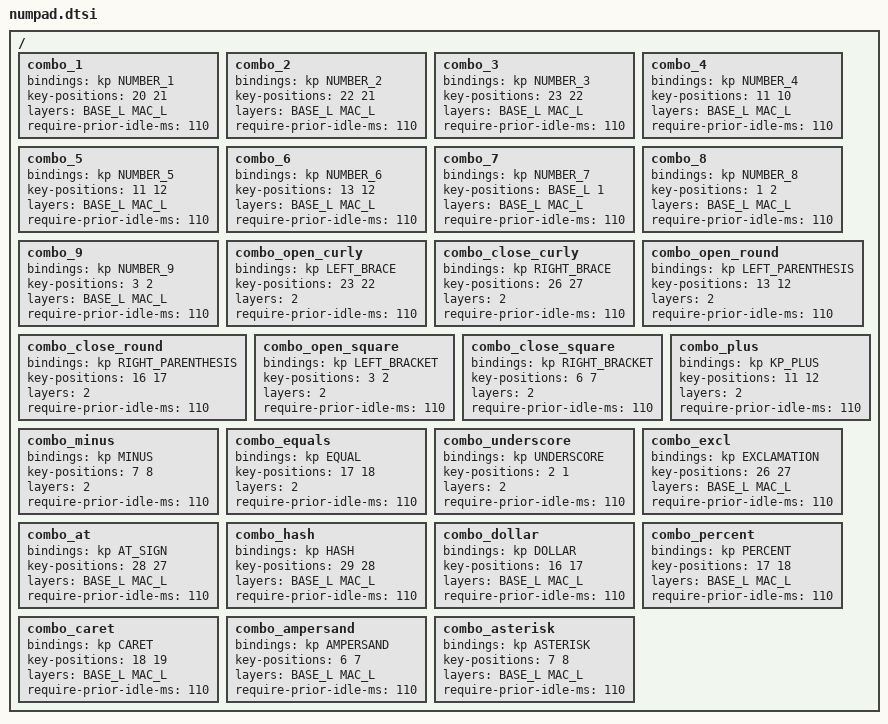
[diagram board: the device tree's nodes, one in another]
/ {
        combo_1 {
            bindings = <&kp NUMBER_1>;
            key-positions = <20 21>;
            layers = <BASE_L MAC_L>;
            require-prior-idle-ms = <110>;
        };
        combo_2 {
            bindings = <&kp NUMBER_2>;
            key-positions = <22 21>;
            layers = <BASE_L MAC_L>;
            require-prior-idle-ms = <110>;
        };
        combo_3 {
            bindings = <&kp NUMBER_3>;
            key-positions = <23 22>;
            layers = <BASE_L MAC_L>;
            require-prior-idle-ms = <110>;
        };
        combo_4 {
            bindings = <&kp NUMBER_4>;
            key-positions = <11 10>;
            layers = <BASE_L MAC_L>;
            require-prior-idle-ms = <110>;
        };
        combo_5 {
            bindings = <&kp NUMBER_5>;
            key-positions = <11 12>;
            layers = <BASE_L MAC_L>;
            require-prior-idle-ms = <110>;
        };
        combo_6 {
            bindings = <&kp NUMBER_6>;
            key-positions = <13 12>;
            layers = <BASE_L MAC_L>;
            require-prior-idle-ms = <110>;
        };
        combo_7 {
            bindings = <&kp NUMBER_7>;
            key-positions = <BASE_L 1>;
            layers = <BASE_L MAC_L>;
            require-prior-idle-ms = <110>;
        };
        combo_8 {
            bindings = <&kp NUMBER_8>;
            key-positions = <1 2>;
            layers = <BASE_L MAC_L>;
            require-prior-idle-ms = <110>;
        };
        combo_9 {
            bindings = <&kp NUMBER_9>;
            key-positions = <3 2>;
            layers = <BASE_L MAC_L>;
            require-prior-idle-ms = <110>;
        };
        // prpgramming combos
        combo_open_curly {
            bindings = <&kp LEFT_BRACE>;
            key-positions = <23 22>;
            layers = <2>;
            require-prior-idle-ms = <110>;
        };
        combo_close_curly {
            bindings = <&kp RIGHT_BRACE>;
            key-positions = <26 27>;
            layers = <2>;
            require-prior-idle-ms = <110>;
        };
        combo_open_round {
            bindings = <&kp LEFT_PARENTHESIS>;
            key-positions = <13 12>;
            layers = <2>;
            require-prior-idle-ms = <110>;
        };
        combo_close_round {
            bindings = <&kp RIGHT_PARENTHESIS>;
            key-positions = <16 17>;
            layers = <2>;
            require-prior-idle-ms = <110>;
        };
        combo_open_square {
            bindings = <&kp LEFT_BRACKET>;
            key-positions = <3 2>;
            layers = <2>;
            require-prior-idle-ms = <110>;
        };
        combo_close_square {
            bindings = <&kp RIGHT_BRACKET>;
            key-positions = <6 7>;
            layers = <2>;
            require-prior-idle-ms = <110>;
        };
        combo_plus {
            bindings = <&kp KP_PLUS>;
            key-positions = <11 12>;
            layers = <2>;
            require-prior-idle-ms = <110>;
        };
        combo_minus {
            bindings = <&kp MINUS>;
            key-positions = <7 8>;
            layers = <2>;
            require-prior-idle-ms = <110>;
        };
        combo_equals {
            bindings = <&kp EQUAL>;
            key-positions = <17 18>;
            layers = <2>;
            require-prior-idle-ms = <110>;
        };
        combo_underscore {
            bindings = <&kp UNDERSCORE>;
            key-positions = <2 1>;
            layers = <2>;
            require-prior-idle-ms = <110>;
        };
        combo_excl {
            bindings = <&kp EXCLAMATION>;
            key-positions = <26 27>;
            layers = <BASE_L MAC_L>;
            require-prior-idle-ms = <110>;
        };
        combo_at {
            bindings = <&kp AT_SIGN>;
            key-positions = <28 27>;
            layers = <BASE_L MAC_L>;
            require-prior-idle-ms = <110>;
        };
        combo_hash {
            bindings = <&kp HASH>;
            key-positions = <29 28>;
            layers = <BASE_L MAC_L>;
            require-prior-idle-ms = <110>;
        };
        combo_dollar {
            bindings = <&kp DOLLAR>;
            key-positions = <16 17>;
            layers = <BASE_L MAC_L>;
            require-prior-idle-ms = <110>;
        };
        combo_percent {
            bindings = <&kp PERCENT>;
            key-positions = <17 18>;
            layers = <BASE_L MAC_L>;
            require-prior-idle-ms = <110>;
        };
        combo_caret {
            bindings = <&kp CARET>;
            key-positions = <18 19>;
            layers = <BASE_L MAC_L>;
            require-prior-idle-ms = <110>;
        };
        combo_ampersand {
            bindings = <&kp AMPERSAND>;
            key-positions = <6 7>;
            layers = <BASE_L MAC_L>;
            require-prior-idle-ms = <110>;
        };
        combo_asterisk {
            bindings = <&kp ASTERISK>;
            key-positions = <7 8>;
            layers = <BASE_L MAC_L>;
            require-prior-idle-ms = <110>;
        };
};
